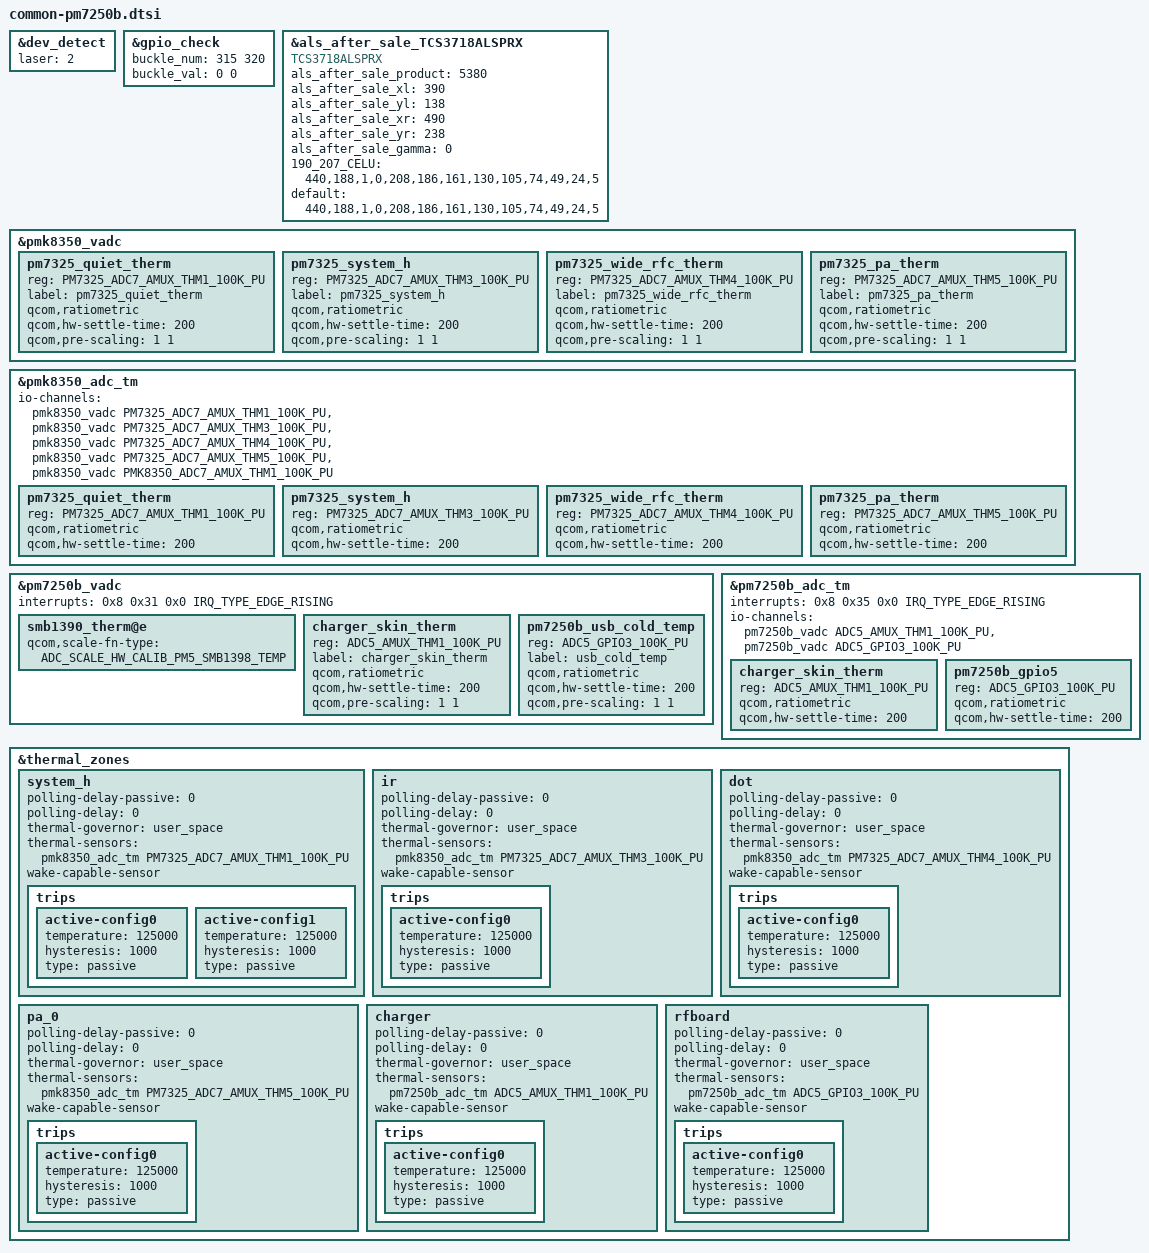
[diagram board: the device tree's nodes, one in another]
#include "../../../yupik-idp-pm7250b.dtsi"
#include "../../common/huawei_dev_detect/huawei_dev_detect.dtsi"
#include "huawei_audio.dtsi"
#include "huawei_bsp.dtsi"
#include "huawei_tp.dtsi"
#include "huawei_mmc.dtsi"
#include "huawei-lcd.dtsi"
#include "huawei_usb.dtsi"
#include "huawei_charger.dtsi"
#include "huawei-sensor.dtsi"
#include "huawei_dp.dtsi"
#include "huawei_ir.dtsi"
#include "huawei_fp.dtsi"
#include "huawei_fac.dtsi"

&dev_detect {
    laser = <2>;
};

/*
 * Each set of pins contains the pin number and pins voltage
 * values, and must end with the names _num and _val.
 */
&gpio_check {
	/* 315: pm8350c gpio03, tlmm BASE = 313 */
	/* 320: pm8350c gpio08, tlmm BASE = 313 */
	buckle_num = "315 320";
	buckle_val = "0 0";
};

&als_after_sale_TCS3718ALSPRX {
    compatible = "TCS3718ALSPRX";
	als_after_sale_product = <5380>;
	als_after_sale_xl = <390>;
	als_after_sale_yl = <138>;
	als_after_sale_xr = <490>;
	als_after_sale_yr = <238>;
	als_after_sale_gamma = <0>;
	190_207_CELU = "440,188,1,0,208,186,161,130,105,74,49,24,5";
	default = "440,188,1,0,208,186,161,130,105,74,49,24,5";
};
&pmk8350_vadc {
	pm7325_quiet_therm {
		reg = <PM7325_ADC7_AMUX_THM1_100K_PU>;
		label = "pm7325_quiet_therm";
		qcom,ratiometric;
		qcom,hw-settle-time = <200>;
		qcom,pre-scaling = <1 1>;
	};

	pm7325_system_h {
		reg = <PM7325_ADC7_AMUX_THM3_100K_PU>;
		label = "pm7325_system_h";
		qcom,ratiometric;
		qcom,hw-settle-time = <200>;
		qcom,pre-scaling = <1 1>;
	};

	pm7325_wide_rfc_therm {
		reg = <PM7325_ADC7_AMUX_THM4_100K_PU>;
		label = "pm7325_wide_rfc_therm";
		qcom,ratiometric;
		qcom,hw-settle-time = <200>;
		qcom,pre-scaling = <1 1>;
	};

	pm7325_pa_therm {
		reg = <PM7325_ADC7_AMUX_THM5_100K_PU>;
		label = "pm7325_pa_therm";
		qcom,ratiometric;
		qcom,hw-settle-time = <200>;
		qcom,pre-scaling = <1 1>;
	};

};

&pmk8350_adc_tm {
	io-channels = <&pmk8350_vadc PM7325_ADC7_AMUX_THM1_100K_PU>,
		<&pmk8350_vadc PM7325_ADC7_AMUX_THM3_100K_PU>,
		<&pmk8350_vadc PM7325_ADC7_AMUX_THM4_100K_PU>,
		<&pmk8350_vadc PM7325_ADC7_AMUX_THM5_100K_PU>,
		<&pmk8350_vadc PMK8350_ADC7_AMUX_THM1_100K_PU>;

	pm7325_quiet_therm {
		reg = <PM7325_ADC7_AMUX_THM1_100K_PU>;
		qcom,ratiometric;
		qcom,hw-settle-time = <200>;
	};

	pm7325_system_h {
		reg = <PM7325_ADC7_AMUX_THM3_100K_PU>;
		qcom,ratiometric;
		qcom,hw-settle-time = <200>;
	};

	pm7325_wide_rfc_therm {
		reg = <PM7325_ADC7_AMUX_THM4_100K_PU>;
		qcom,ratiometric;
		qcom,hw-settle-time = <200>;
	};

	pm7325_pa_therm {
		reg = <PM7325_ADC7_AMUX_THM5_100K_PU>;
		qcom,ratiometric;
		qcom,hw-settle-time = <200>;
	};

};

&pm7250b_vadc {
	interrupts = <0x8 0x31 0x0 IRQ_TYPE_EDGE_RISING>;

	smb1390_therm@e {
		qcom,scale-fn-type = <ADC_SCALE_HW_CALIB_PM5_SMB1398_TEMP>;
	};

	charger_skin_therm {
		reg = <ADC5_AMUX_THM1_100K_PU>;
		label = "charger_skin_therm";
		qcom,ratiometric;
		qcom,hw-settle-time = <200>;
		qcom,pre-scaling = <1 1>;
	};

	pm7250b_usb_cold_temp {
		reg = <ADC5_GPIO3_100K_PU>;
		label = "usb_cold_temp";
		qcom,ratiometric;
		qcom,hw-settle-time = <200>;
		qcom,pre-scaling = <1 1>;
	};
};

&pm7250b_adc_tm {
	interrupts = <0x8 0x35 0x0 IRQ_TYPE_EDGE_RISING>;

	io-channels = <&pm7250b_vadc ADC5_AMUX_THM1_100K_PU>,
			<&pm7250b_vadc ADC5_GPIO3_100K_PU>;

	charger_skin_therm {
		reg = <ADC5_AMUX_THM1_100K_PU>;
		qcom,ratiometric;
		qcom,hw-settle-time = <200>;
	};

	pm7250b_gpio5 {
		reg = <ADC5_GPIO3_100K_PU>;
		qcom,ratiometric;
		qcom,hw-settle-time = <200>;
	};
};

&thermal_zones {
	system_h {
		polling-delay-passive = <0>;
		polling-delay = <0>;
		thermal-governor = "user_space";
		thermal-sensors = <&pmk8350_adc_tm PM7325_ADC7_AMUX_THM1_100K_PU>;
		wake-capable-sensor;
		trips {
			active-config0 {
				temperature = <125000>;
				hysteresis = <1000>;
				type = "passive";
			};

			active-config1 {
				temperature = <125000>;
				hysteresis = <1000>;
				type = "passive";
			};
		};
	};

	ir{
		polling-delay-passive = <0>;
		polling-delay = <0>;
		thermal-governor = "user_space";
		thermal-sensors = <&pmk8350_adc_tm PM7325_ADC7_AMUX_THM3_100K_PU>;
		wake-capable-sensor;
		trips {
			active-config0 {
				temperature = <125000>;
				hysteresis = <1000>;
				type = "passive";
			};
		};
	};

	dot {
		polling-delay-passive = <0>;
		polling-delay = <0>;
		thermal-governor = "user_space";
		thermal-sensors = <&pmk8350_adc_tm PM7325_ADC7_AMUX_THM4_100K_PU>;
		wake-capable-sensor;
		trips {
			active-config0 {
				temperature = <125000>;
				hysteresis = <1000>;
				type = "passive";
			};
		};
	};

	pa_0 {
		polling-delay-passive = <0>;
		polling-delay = <0>;
		thermal-governor = "user_space";
		thermal-sensors = <&pmk8350_adc_tm PM7325_ADC7_AMUX_THM5_100K_PU>;
		wake-capable-sensor;
		trips {
			active-config0 {
				temperature = <125000>;
				hysteresis = <1000>;
				type = "passive";
			};
		};
	};

	charger {
		polling-delay-passive = <0>;
		polling-delay = <0>;
		thermal-governor = "user_space";
		thermal-sensors = <&pm7250b_adc_tm ADC5_AMUX_THM1_100K_PU>;
		wake-capable-sensor;
		trips {
			active-config0 {
				temperature = <125000>;
				hysteresis = <1000>;
				type = "passive";
			};
		};
	};

	rfboard {
		polling-delay-passive = <0>;
		polling-delay = <0>;
		thermal-governor = "user_space";
		thermal-sensors = <&pm7250b_adc_tm ADC5_GPIO3_100K_PU>;
		wake-capable-sensor;
		trips {
			active-config0 {
				temperature = <125000>;
				hysteresis = <1000>;
				type = "passive";
			};
		};
	};

};
